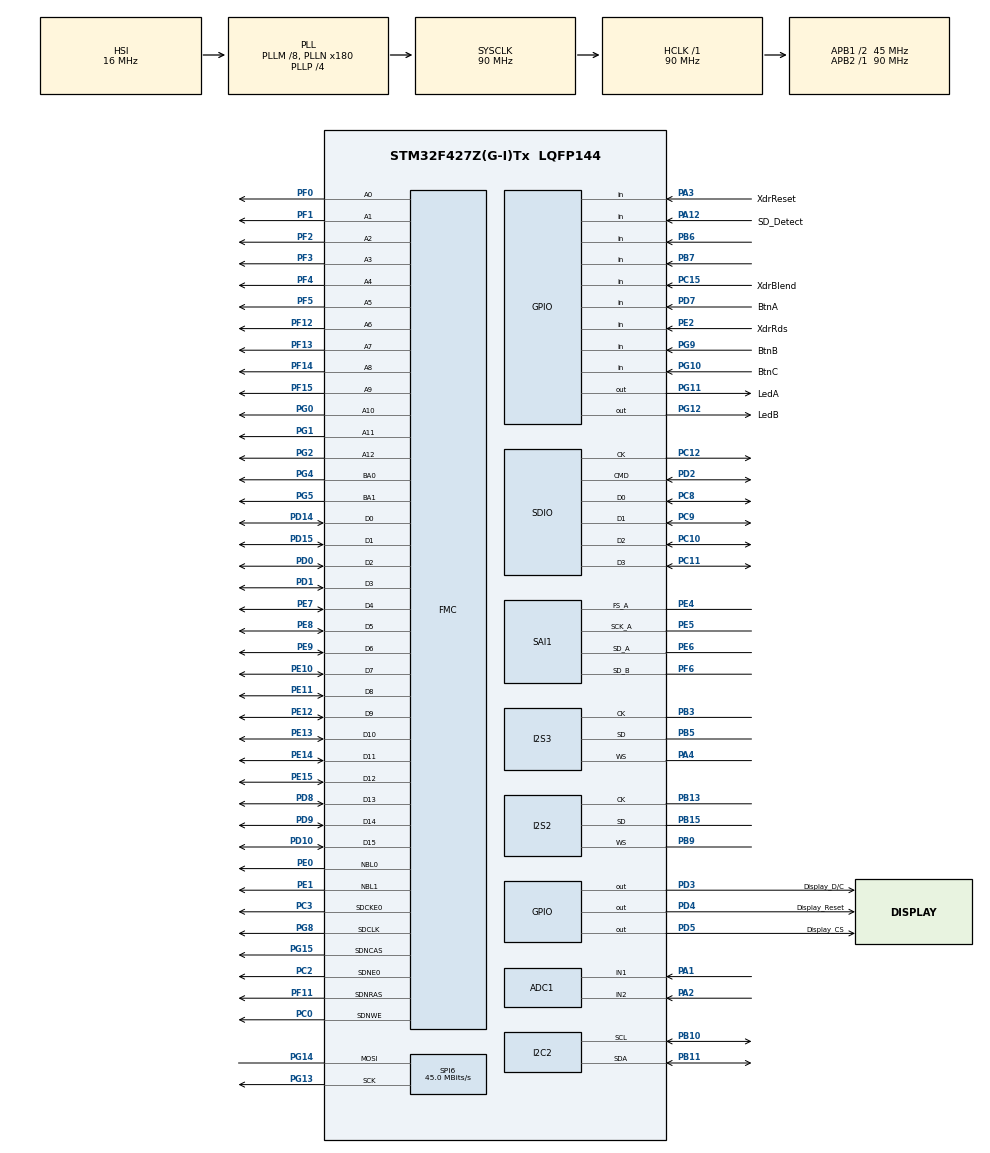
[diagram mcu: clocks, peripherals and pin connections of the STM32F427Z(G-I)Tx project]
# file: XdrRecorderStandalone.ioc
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ADC1.Channel-3\#ChannelRegularConversion=ADC_CHANNEL_1
ADC1.NbrOfConversionFlag=1
ADC1.Rank-3\#ChannelRegularConversion=1
ADC1.SamplingTime-3\#ChannelRegularConversion=ADC_SAMPLETIME_3CYCLES
ADC1.master=1
DMA2D.ColorMode=DMA2D_OUTPUT_RGB565
DMA2D.OutputOffset=1
Dma.Request0=SAI1_A
Dma.Request1=SAI1_B
Dma.Request2=SPI2_RX
Dma.Request3=SPI6_TX
Dma.Request4=SDIO_RX
Dma.Request5=SDIO_TX
Dma.SAI1_A.0.Direction=DMA_PERIPH_TO_MEMORY
Dma.SAI1_A.0.FIFOMode=DMA_FIFOMODE_DISABLE
Dma.SAI1_A.0.Instance=DMA2_Stream1
Dma.SAI1_A.0.MemDataAlignment=DMA_MDATAALIGN_WORD
Dma.SAI1_A.0.MemInc=DMA_MINC_ENABLE
Dma.SAI1_A.0.Mode=DMA_CIRCULAR
Dma.SAI1_A.0.PeriphDataAlignment=DMA_PDATAALIGN_WORD
Dma.SAI1_A.0.PeriphInc=DMA_PINC_DISABLE
Dma.SAI1_A.0.Priority=DMA_PRIORITY_HIGH
Dma.SAI1_B.1.Direction=DMA_PERIPH_TO_MEMORY
Dma.SAI1_B.1.FIFOMode=DMA_FIFOMODE_DISABLE
Dma.SAI1_B.1.Instance=DMA2_Stream4
Dma.SAI1_B.1.MemDataAlignment=DMA_MDATAALIGN_HALFWORD
Dma.SAI1_B.1.MemInc=DMA_MINC_ENABLE
Dma.SAI1_B.1.Mode=DMA_CIRCULAR
Dma.SAI1_B.1.PeriphDataAlignment=DMA_PDATAALIGN_HALFWORD
Dma.SAI1_B.1.PeriphInc=DMA_PINC_DISABLE
Dma.SAI1_B.1.Priority=DMA_PRIORITY_HIGH
Dma.SDIO_RX.4.Direction=DMA_PERIPH_TO_MEMORY
Dma.SDIO_RX.4.FIFOMode=DMA_FIFOMODE_ENABLE
Dma.SDIO_RX.4.FIFOThreshold=DMA_FIFO_THRESHOLD_FULL
Dma.SDIO_RX.4.Instance=DMA2_Stream3
Dma.SDIO_RX.4.MemBurst=DMA_MBURST_INC4
Dma.SDIO_RX.4.MemDataAlignment=DMA_MDATAALIGN_WORD
Dma.SDIO_RX.4.MemInc=DMA_MINC_ENABLE
Dma.SDIO_RX.4.Mode=DMA_PFCTRL
Dma.SDIO_RX.4.PeriphBurst=DMA_PBURST_INC4
Dma.SDIO_RX.4.PeriphDataAlignment=DMA_PDATAALIGN_WORD
Dma.SDIO_RX.4.PeriphInc=DMA_PINC_DISABLE
Dma.SDIO_RX.4.Priority=DMA_PRIORITY_VERY_HIGH
Dma.SDIO_TX.5.Direction=DMA_MEMORY_TO_PERIPH
Dma.SDIO_TX.5.FIFOMode=DMA_FIFOMODE_ENABLE
Dma.SDIO_TX.5.FIFOThreshold=DMA_FIFO_THRESHOLD_FULL
Dma.SDIO_TX.5.Instance=DMA2_Stream6
Dma.SDIO_TX.5.MemBurst=DMA_MBURST_INC4
Dma.SDIO_TX.5.MemDataAlignment=DMA_MDATAALIGN_WORD
Dma.SDIO_TX.5.MemInc=DMA_MINC_ENABLE
Dma.SDIO_TX.5.Mode=DMA_PFCTRL
Dma.SDIO_TX.5.PeriphBurst=DMA_PBURST_INC4
Dma.SDIO_TX.5.PeriphDataAlignment=DMA_PDATAALIGN_WORD
Dma.SDIO_TX.5.PeriphInc=DMA_PINC_DISABLE
Dma.SDIO_TX.5.Priority=DMA_PRIORITY_VERY_HIGH
Dma.SPI2_RX.2.Direction=DMA_PERIPH_TO_MEMORY
Dma.SPI2_RX.2.FIFOMode=DMA_FIFOMODE_DISABLE
Dma.SPI2_RX.2.Instance=DMA1_Stream3
Dma.SPI2_RX.2.MemDataAlignment=DMA_MDATAALIGN_WORD
Dma.SPI2_RX.2.MemInc=DMA_MINC_ENABLE
Dma.SPI2_RX.2.Mode=DMA_CIRCULAR
Dma.SPI2_RX.2.PeriphDataAlignment=DMA_PDATAALIGN_WORD
Dma.SPI2_RX.2.PeriphInc=DMA_PINC_DISABLE
Dma.SPI2_RX.2.Priority=DMA_PRIORITY_HIGH
Dma.SPI6_TX.3.Direction=DMA_MEMORY_TO_PERIPH
Dma.SPI6_TX.3.FIFOMode=DMA_FIFOMODE_DISABLE
Dma.SPI6_TX.3.Instance=DMA2_Stream5
Dma.SPI6_TX.3.MemDataAlignment=DMA_MDATAALIGN_BYTE
Dma.SPI6_TX.3.MemInc=DMA_MINC_ENABLE
Dma.SPI6_TX.3.Mode=DMA_NORMAL
Dma.SPI6_TX.3.PeriphDataAlignment=DMA_PDATAALIGN_BYTE
Dma.SPI6_TX.3.PeriphInc=DMA_PINC_DISABLE
Dma.SPI6_TX.3.Priority=DMA_PRIORITY_LOW
FATFS.BSP.number=1
FATFS.USE_DMA_CODE_SD=1
FATFS._FS_EXFAT=1
FATFS._USE_LFN=3
FATFS0.BSP.STBoard=false
FATFS0.BSP.api=Unknown
FATFS0.BSP.instance=PA12
FATFS0.BSP.ip=GPIO
FATFS0.BSP.mode=Input
FATFS0.BSP.name=Detect_SDIO
FATFS0.BSP.solution=PA12
FMC.CASLatency1=FMC_SDRAM_CAS_LATENCY_3
FMC.ColumnBitsNumber1=FMC_SDRAM_COLUMN_BITS_NUM_9
FMC.ExitSelfRefreshDelay1=8
FMC.LoadToActiveDelay1=2
FMC.RCDDelay1=2
FMC.RPDelay1=2
FMC.ReadBurst1=FMC_SDRAM_RBURST_ENABLE
FMC.ReadPipeDelay1=FMC_SDRAM_RPIPE_DELAY_1
FMC.RowCycleDelay1=7
FMC.SDClockPeriod1=FMC_SDRAM_CLOCK_PERIOD_2
FMC.SelfRefreshTime1=6
FMC.WriteRecoveryTime1=5
I2C2.I2C_Mode=I2C_Fast
I2S2.AudioFreq=I2S_AUDIOFREQ_44K
I2S2.DataFormat=I2S_DATAFORMAT_32B
I2S2.ErrorAudioFreq=0.26 %
I2S2.FullDuplexMode=I2S_FULLDUPLEXMODE_DISABLE
I2S2.Instance=SPI$Index
I2S2.Mode=I2S_MODE_SLAVE_RX
I2S2.RealAudioFreq=44.117 KHz
I2S2.VirtualMode=I2S_MODE_SLAVE
I2S3.AudioFreq=I2S_AUDIOFREQ_44K
I2S3.ErrorAudioFreq=0.26 %
I2S3.FullDuplexMode=I2S_FULLDUPLEXMODE_DISABLE
I2S3.Instance=SPI$Index
I2S3.RealAudioFreq=44.117 KHz
I2S3.VirtualMode=I2S_MODE_SLAVE
Mcu.Family=STM32F4
Mcu.Name=STM32F427Z(G-I)Tx
Mcu.Package=LQFP144
NVIC.DMA1_Stream3_IRQn=true\:0\:0\:false\:false\:true\:false\:true\:true
NVIC.DMA2D_IRQn=true\:0\:0\:false\:false\:true\:true\:true\:true
NVIC.DMA2_Stream1_IRQn=true\:14\:0\:true\:false\:true\:false\:true\:true
NVIC.DMA2_Stream3_IRQn=true\:0\:0\:false\:false\:true\:false\:true\:true
NVIC.DMA2_Stream4_IRQn=true\:14\:0\:true\:false\:true\:false\:true\:true
NVIC.DMA2_Stream5_IRQn=true\:0\:0\:false\:false\:true\:false\:true\:true
NVIC.DMA2_Stream6_IRQn=true\:0\:0\:false\:false\:true\:false\:true\:true
NVIC.FMC_IRQn=true\:0\:0\:false\:false\:true\:true\:true\:true
NVIC.PriorityGroup=NVIC_PRIORITYGROUP_4
NVIC.SAI1_IRQn=true\:0\:0\:false\:false\:true\:true\:true\:true
NVIC.SDIO_IRQn=true\:0\:0\:true\:false\:true\:true\:true\:true
NVIC.SPI2_IRQn=true\:0\:0\:false\:false\:true\:true\:true\:true
NVIC.SPI6_IRQn=true\:0\:0\:false\:false\:true\:true\:true\:true
PA1.Signal=ADCx_IN1
PA12.GPIO_Label=SD_Detect
PA12.Signal=GPIO_Input
PA13.Mode=Serial_Wire
PA13.Signal=SYS_JTMS-SWDIO
PA14.Mode=Serial_Wire
PA14.Signal=SYS_JTCK-SWCLK
PA2.Signal=ADCx_IN2
PA3.GPIO_Label=XdrReset
PA3.Signal=GPIO_Input
PA4.Mode=Half_Duplex_Slave
PA4.Signal=I2S3_WS
PB10.Mode=I2C
PB10.Signal=I2C2_SCL
PB11.Mode=I2C
PB11.Signal=I2C2_SDA
PB13.Mode=Half_Duplex_Slave
PB13.Signal=I2S2_CK
PB15.Mode=Half_Duplex_Slave
PB15.Signal=I2S2_SD
PB3.Mode=Half_Duplex_Slave
PB3.Signal=I2S3_CK
PB5.Mode=Half_Duplex_Slave
PB5.Signal=I2S3_SD
PB6.Signal=GPIO_Input
PB7.Signal=GPIO_Input
PB9.Mode=Half_Duplex_Slave
PB9.Signal=I2S2_WS
PC0.Signal=FMC_SDNWE
PC10.Mode=SD_4_bits_Wide_bus
PC10.Signal=SDIO_D2
PC11.Mode=SD_4_bits_Wide_bus
PC11.Signal=SDIO_D3
PC12.Mode=SD_4_bits_Wide_bus
PC12.Signal=SDIO_CK
PC15/OSC32_OUT.GPIO_Label=XdrBlend
PC15/OSC32_OUT.Signal=GPIO_Input
PC2.Mode=SdramChipSelect1_1
PC2.Signal=FMC_SDNE0
PC3.Mode=SdramChipSelect1_1
PC3.Signal=FMC_SDCKE0
PC8.Mode=SD_4_bits_Wide_bus
PC8.Signal=SDIO_D0
PC9.Mode=SD_4_bits_Wide_bus
PC9.Signal=SDIO_D1
PD0.Signal=FMC_D2_DA2
PD1.Signal=FMC_D3_DA3
PD10.Signal=FMC_D15_DA15
PD14.Signal=FMC_D0_DA0
PD15.Signal=FMC_D1_DA1
PD2.Mode=SD_4_bits_Wide_bus
PD2.Signal=SDIO_CMD
PD3.GPIO_Label=Display_D/C
PD3.Signal=GPIO_Output
PD4.GPIO_Label=Display_Reset
PD4.Signal=GPIO_Output
PD5.GPIO_Label=Display_CS
PD5.Signal=GPIO_Output
PD7.GPIO_Label=BtnA
PD7.Signal=GPIO_Input
PD8.Signal=FMC_D13_DA13
PD9.Signal=FMC_D14_DA14
PE0.Signal=FMC_NBL0
PE1.Signal=FMC_NBL1
PE10.Signal=FMC_D7_DA7
PE11.Signal=FMC_D8_DA8
PE12.Signal=FMC_D9_DA9
PE13.Signal=FMC_D10_DA10
PE14.Signal=FMC_D11_DA11
PE15.Signal=FMC_D12_DA12
PE2.GPIO_Label=XdrRds
PE2.Signal=GPIO_Input
PE4.GPIO_PuPd=GPIO_PULLDOWN
PE4.Mode=SAI_A_AsyncSlave
PE4.Signal=SAI1_FS_A
PE5.GPIO_PuPd=GPIO_PULLDOWN
PE5.Mode=SAI_A_AsyncSlave
PE5.Signal=SAI1_SCK_A
PE6.GPIO_PuPd=GPIO_PULLDOWN
PE6.Mode=SAI_A_AsyncSlave
PE6.Signal=SAI1_SD_A
PE7.Signal=FMC_D4_DA4
PE8.Signal=FMC_D5_DA5
PE9.Signal=FMC_D6_DA6
PF0.Signal=FMC_A0
PF1.Signal=FMC_A1
PF11.Signal=FMC_SDNRAS
PF12.Signal=FMC_A6
PF13.Signal=FMC_A7
PF14.Signal=FMC_A8
PF15.Signal=FMC_A9
PF2.Signal=FMC_A2
PF3.Signal=FMC_A3
PF4.Signal=FMC_A4
PF5.Signal=FMC_A5
PF6.GPIO_PuPd=GPIO_PULLDOWN
PF6.Mode=SAI_B_SyncSlave
PF6.Signal=SAI1_SD_B
PG0.Signal=FMC_A10
PG1.Signal=FMC_A11
PG10.GPIO_Label=BtnC
PG10.Signal=GPIO_Input
PG11.GPIO_Label=LedA
PG11.Signal=GPIO_Output
PG12.GPIO_Label=LedB
PG12.Signal=GPIO_Output
PG13.Mode=Simplex_Bidirectional_Master
PG13.Signal=SPI6_SCK
PG14.Mode=Simplex_Bidirectional_Master
PG14.Signal=SPI6_MOSI
PG15.Signal=FMC_SDNCAS
PG2.Signal=FMC_A12
PG4.Signal=FMC_A14_BA0
PG5.Signal=FMC_A15_BA1
PG8.Signal=FMC_SDCLK
PG9.GPIO_Label=BtnB
PG9.Signal=GPIO_Input
ProjectManager.HeapSize=0x200
ProjectManager.StackSize=0x400
ProjectManager.TargetToolchain=STM32CubeIDE
RCC.48MHZClocksFreq_Value=36000000
RCC.AHBFreq_Value=90000000
RCC.APB1CLKDivider=RCC_HCLK_DIV2
RCC.APB1Freq_Value=45000000
RCC.APB1TimFreq_Value=90000000
RCC.APB2Freq_Value=90000000
RCC.APB2TimFreq_Value=90000000
RCC.CortexFreq_Value=90000000
RCC.DATA_CACHE_ENABLE=0
RCC.HCLKFreq_Value=90000000
RCC.HSE_VALUE=25000000
RCC.HSI_VALUE=16000000
RCC.LSE_VALUE=32768
RCC.PLLI2SQ=8
RCC.PLLM=8
RCC.PLLN=180
RCC.PLLP=RCC_PLLP_DIV4
RCC.PLLQ=10
RCC.PLLSAIN=120
RCC.PLLSAIQ=2
RCC.PREFETCH_ENABLE=0
RCC.SYSCLKFreq_VALUE=90000000
RCC.SYSCLKSource=RCC_SYSCLKSOURCE_PLLCLK
RCC.VCOOutputFreq_Value=360000000
SAI1.ActiveFrameLength-SAI_A_AsyncSlave=16
SAI1.ActiveFrameLength-SAI_B_SyncSlave=16
SAI1.ClockStrobing-SAI_A_AsyncSlave=SAI_CLOCKSTROBING_RISINGEDGE
SAI1.ClockStrobing-SAI_B_SyncSlave=SAI_CLOCKSTROBING_RISINGEDGE
SAI1.DataSize-SAI_A_AsyncSlave=SAI_DATASIZE_16
SAI1.DataSize-SAI_B_SyncSlave=SAI_DATASIZE_16
SAI1.FIFOThreshold-SAI_A_AsyncSlave=SAI_FIFOTHRESHOLD_EMPTY
SAI1.FIFOThreshold-SAI_B_SyncSlave=SAI_FIFOTHRESHOLD_EMPTY
SAI1.FSDefinition-SAI_A_AsyncSlave=SAI_FS_STARTFRAME
SAI1.FSDefinition-SAI_B_SyncSlave=SAI_FS_STARTFRAME
SAI1.FSOffset-SAI_A_AsyncSlave=SAI_FS_BEFOREFIRSTBIT
SAI1.FSOffset-SAI_B_SyncSlave=SAI_FS_BEFOREFIRSTBIT
SAI1.FSPolarity-SAI_A_AsyncSlave=SAI_FS_ACTIVE_LOW
SAI1.FSPolarity-SAI_B_SyncSlave=SAI_FS_ACTIVE_LOW
SAI1.FirstBitOffset-SAI_A_AsyncSlave=0
SAI1.FrameLength-SAI_A_AsyncSlave=32
SAI1.FrameLength-SAI_B_SyncSlave=32
SAI1.Instance-SAI_A_AsyncSlave=SAI$Index_Block_A
SAI1.Instance-SAI_B_SyncSlave=SAI$Index_Block_B
SAI1.SlotActive-SAI_A_AsyncSlave=0x0000FFFF
SAI1.SlotActive-SAI_B_SyncSlave=0x0000FFFF
SAI1.SlotNumber-SAI_A_AsyncSlave=2
SAI1.SlotNumber-SAI_B_SyncSlave=2
SAI1.SlotSize-SAI_A_AsyncSlave=SAI_SLOTSIZE_16B
SAI1.SlotSize-SAI_B_SyncSlave=SAI_SLOTSIZE_16B
SAI1.Synchro_A=SAI_ASYNCHRONOUS
SAI1.Synchro_B=SAI_SYNCHRONOUS
SAI1.VirtualMode-SAI_A_AsyncSlave=VM_SLAVE
SAI1.VirtualMode-SAI_B_SyncSlave=VM_SLAVE
SAI1.VirtualSlotActive-SAI_A_AsyncSlave=SAI_SLOTACTIVE_ALL
SAI1.VirtualSlotActive-SAI_B_SyncSlave=SAI_SLOTACTIVE_ALL
SDIO.ClockDiv=0
SH.ADCx_IN1.0=ADC1_IN1,IN1
SH.ADCx_IN2.0=ADC1_IN2,IN2
SH.FMC_A0.0=FMC_A0,13b-sda1
SH.FMC_A1.0=FMC_A1,13b-sda1
SH.FMC_A10.0=FMC_A10,13b-sda1
SH.FMC_A11.0=FMC_A11,13b-sda1
SH.FMC_A12.0=FMC_A12,13b-sda1
SH.FMC_A14_BA0.0=FMC_BA0,FourSdramBanks1
SH.FMC_A15_BA1.0=FMC_BA1,FourSdramBanks1
SH.FMC_A2.0=FMC_A2,13b-sda1
SH.FMC_A3.0=FMC_A3,13b-sda1
SH.FMC_A4.0=FMC_A4,13b-sda1
SH.FMC_A5.0=FMC_A5,13b-sda1
SH.FMC_A6.0=FMC_A6,13b-sda1
SH.FMC_A7.0=FMC_A7,13b-sda1
SH.FMC_A8.0=FMC_A8,13b-sda1
SH.FMC_A9.0=FMC_A9,13b-sda1
SH.FMC_D0_DA0.0=FMC_D0,sd-16b-d1
SH.FMC_D10_DA10.0=FMC_D10,sd-16b-d1
SH.FMC_D11_DA11.0=FMC_D11,sd-16b-d1
SH.FMC_D12_DA12.0=FMC_D12,sd-16b-d1
SH.FMC_D13_DA13.0=FMC_D13,sd-16b-d1
SH.FMC_D14_DA14.0=FMC_D14,sd-16b-d1
SH.FMC_D15_DA15.0=FMC_D15,sd-16b-d1
SH.FMC_D1_DA1.0=FMC_D1,sd-16b-d1
SH.FMC_D2_DA2.0=FMC_D2,sd-16b-d1
SH.FMC_D3_DA3.0=FMC_D3,sd-16b-d1
SH.FMC_D4_DA4.0=FMC_D4,sd-16b-d1
SH.FMC_D5_DA5.0=FMC_D5,sd-16b-d1
SH.FMC_D6_DA6.0=FMC_D6,sd-16b-d1
SH.FMC_D7_DA7.0=FMC_D7,sd-16b-d1
SH.FMC_D8_DA8.0=FMC_D8,sd-16b-d1
SH.FMC_D9_DA9.0=FMC_D9,sd-16b-d1
SH.FMC_NBL0.0=FMC_NBL0,Sd2ByteEnable1
SH.FMC_NBL1.0=FMC_NBL1,Sd2ByteEnable1
SH.FMC_SDCLK.0=FMC_SDCLK,13b-sda1
SH.FMC_SDNCAS.0=FMC_SDNCAS,13b-sda1
SH.FMC_SDNRAS.0=FMC_SDNRAS,13b-sda1
SH.FMC_SDNWE.0=FMC_SDNWE,13b-sda1
SPI6.BaudRatePrescaler=SPI_BAUDRATEPRESCALER_2
SPI6.CalculateBaudRate=45.0 MBits/s
SPI6.Direction=SPI_DIRECTION_1LINE
SPI6.Mode=SPI_MODE_MASTER
SPI6.VirtualType=VM_MASTER
VP_DMA2D_VS_DMA2D.Mode=DMA2D_Activate
VP_FATFS_VS_SDIO.Mode=SDIO
board=custom

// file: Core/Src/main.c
/* USER CODE BEGIN Header */
/**
  ******************************************************************************
  * @file           : main.c
  * @brief          : Main program body
  ******************************************************************************
  * @attention
  *
  * Copyright (c) 2022 STMicroelectronics.
  * All rights reserved.
  *
  * This software is licensed under terms that can be found in the LICENSE file
  * in the root directory of this software component.
  * If no LICENSE file comes with this software, it is provided AS-IS.
  *
  ******************************************************************************
  */
/* USER CODE END Header */
#include <gui/views/captureview.h>
#include "main.h"
#include "fatfs.h"

/* USER CODE BEGIN Includes */
#include "sdram.h"
#include "recorder/recorder.h"
#include "recorder/wav.h"
#include "sdman.h"
#include "gui/assets.h"
#include "gui/display.h"
#include "gui/viewman.h"
#include "gui/views/splash.h"
/* USER CODE END Includes */

ADC_HandleTypeDef hadc1;

DMA2D_HandleTypeDef hdma2d;

I2C_HandleTypeDef hi2c2;

I2S_HandleTypeDef hi2s2;
I2S_HandleTypeDef hi2s3;
DMA_HandleTypeDef hdma_spi2_rx;

SAI_HandleTypeDef hsai_BlockA1;
SAI_HandleTypeDef hsai_BlockB1;
DMA_HandleTypeDef hdma_sai1_a;
DMA_HandleTypeDef hdma_sai1_b;

SD_HandleTypeDef hsd;
DMA_HandleTypeDef hdma_sdio_rx;
DMA_HandleTypeDef hdma_sdio_tx;

SPI_HandleTypeDef hspi6;
DMA_HandleTypeDef hdma_spi6_tx;

SDRAM_HandleTypeDef hsdram1;

void SystemClock_Config(void);
void PeriphCommonClock_Config(void);
static void MX_GPIO_Init(void);
static void MX_DMA_Init(void);
static void MX_DMA2D_Init(void);
static void MX_FMC_Init(void);
static void MX_I2S2_Init(void);
static void MX_I2S3_Init(void);
static void MX_SAI1_Init(void);
static void MX_SDIO_SD_Init(void);
static void MX_SPI6_Init(void);
static void MX_I2C2_Init(void);
static void MX_ADC1_Init(void);

/* USER CODE BEGIN 0 */

// USER IMPLIMENTED - Called when a recorder starts. Output should be opened. Returns 1 on success, otherwise 0
int recorder_handler_begin(int index, FIL* output) {
	//Open file
	if (f_open(output, "0:/test.wav", FA_CREATE_ALWAYS | FA_WRITE) != FR_OK)
		return 0;

	//Query
	recorder_class_t info;
	uint8_t state;
	uint64_t receivedSamples;
	uint64_t droppedBuffers;
	recorder_query_instance_info(index, &info, &state, &receivedSamples, &droppedBuffers);

	//Prepare WAV header
	wav_file_header_t wav;
	wav_init_header(&wav, info.output_channels, info.output_bits_per_sample, info.output_sample_rate);
	UINT written;
	f_write(output, &wav, sizeof(wav), &written);
	return 1;
}

// USER IMPLIMENTED - Called when a recorder stops (either normally or with an error). File should be closed by this function.
void recorder_handler_stop(int index, FIL* output, int code) {
	//Query
	recorder_class_t info;
	uint8_t state;
	uint64_t receivedSamples;
	uint64_t droppedBuffers;
	recorder_query_instance_info(index, &info, &state, &receivedSamples, &droppedBuffers);

	//Prepare WAV header
	wav_file_header_t wav;
	wav_init_header(&wav, info.output_channels, info.output_bits_per_sample, info.output_sample_rate);
	wav_calculate_length(&wav, receivedSamples);

	//Rewind to beginning and update WAV header
	UINT written;
	f_lseek(output, 0);
	f_write(output, &wav, sizeof(wav), &written);

	//Finally, close file
	f_close(output);
}

/* USER CODE END 0 */

int main(void)
{

  /* MCU Configuration--------------------------------------------------------*/

  /* Reset of all peripherals, Initializes the Flash interface and the Systick. */
  HAL_Init();

  /* Configure the system clock */
  SystemClock_Config();

/* Configure the peripherals common clocks */
  PeriphCommonClock_Config();

  /* Initialize all configured peripherals */
  MX_GPIO_Init();
  MX_DMA_Init();
  MX_DMA2D_Init();
  MX_FMC_Init();
  MX_I2S2_Init();
  MX_I2S3_Init();
  MX_SAI1_Init();
  MX_SDIO_SD_Init();
  MX_SPI6_Init();
  MX_I2C2_Init();
  MX_ADC1_Init();
  MX_FATFS_Init();
  /* USER CODE BEGIN 2 */

  /*uint32_t test[64];
  HAL_StatusTypeDef result;
  int count = 0;
  do {
	  result = HAL_SAI_Receive(&hsai_BlockA1, test, 64, 9999);
	  count++;
  } while (result == HAL_OK);*/

  //int code = f_mount(&sdman_fs, SDPath, 1);

  //Start the display
  HAL_Delay(250);
  display_fb_clear();
  display_init();
  create_view_splash();
  viewman_tick();

  //Show capture view
  create_view_capture();
  viewman_push_alert(&icon_alert_warn, "SD IO Err!");
  int test = 0;

  /* USER CODE END 2 */

  /* Infinite loop */
  /* USER CODE BEGIN WHILE */
  while (1)
  {
	  //Tick SD card manager
	  sdman_tick();

	  //TEST
	  if (!test && sdman_state == SDMAN_STATE_READY) {
		  recorder_request_start(0);
		  test = 1;
	  }

	  //Tick view
	  viewman_tick();
    /* USER CODE END WHILE */

  }
}

void SystemClock_Config(void)
{
  RCC_OscInitTypeDef RCC_OscInitStruct = {0};
  RCC_ClkInitTypeDef RCC_ClkInitStruct = {0};

  /** Macro to configure SAI1BlockB clock source selection
  */
  __HAL_RCC_SAI_BLOCKBCLKSOURCE_CONFIG(SAI_CLKSOURCE_PLLSAI);

  /** Macro to configure SAI1BlockA clock source selection
  */
  __HAL_RCC_SAI_BLOCKACLKSOURCE_CONFIG(SAI_CLKSOURCE_PLLSAI);

  /** Configure the main internal regulator output voltage
  */
  __HAL_RCC_PWR_CLK_ENABLE();
  __HAL_PWR_VOLTAGESCALING_CONFIG(PWR_REGULATOR_VOLTAGE_SCALE3);

  /** Initializes the RCC Oscillators according to the specified parameters
  * in the RCC_OscInitTypeDef structure.
  */
  RCC_OscInitStruct.OscillatorType = RCC_OSCILLATORTYPE_HSI;
  RCC_OscInitStruct.HSIState = RCC_HSI_ON;
  RCC_OscInitStruct.HSICalibrationValue = RCC_HSICALIBRATION_DEFAULT;
  RCC_OscInitStruct.PLL.PLLState = RCC_PLL_ON;
  RCC_OscInitStruct.PLL.PLLSource = RCC_PLLSOURCE_HSI;
  RCC_OscInitStruct.PLL.PLLM = 8;
  RCC_OscInitStruct.PLL.PLLN = 180;
  RCC_OscInitStruct.PLL.PLLP = RCC_PLLP_DIV4;
  RCC_OscInitStruct.PLL.PLLQ = 10;
  if (HAL_RCC_OscConfig(&RCC_OscInitStruct) != HAL_OK)
  {
    Error_Handler();
  }

  /** Activate the Over-Drive mode
  */
  if (HAL_PWREx_EnableOverDrive() != HAL_OK)
  {
    Error_Handler();
  }

  /** Initializes the CPU, AHB and APB buses clocks
  */
  RCC_ClkInitStruct.ClockType = RCC_CLOCKTYPE_HCLK|RCC_CLOCKTYPE_SYSCLK
                              |RCC_CLOCKTYPE_PCLK1|RCC_CLOCKTYPE_PCLK2;
  RCC_ClkInitStruct.SYSCLKSource = RCC_SYSCLKSOURCE_PLLCLK;
  RCC_ClkInitStruct.AHBCLKDivider = RCC_SYSCLK_DIV1;
  RCC_ClkInitStruct.APB1CLKDivider = RCC_HCLK_DIV2;
  RCC_ClkInitStruct.APB2CLKDivider = RCC_HCLK_DIV1;

  if (HAL_RCC_ClockConfig(&RCC_ClkInitStruct, FLASH_LATENCY_2) != HAL_OK)
  {
    Error_Handler();
  }
}

void PeriphCommonClock_Config(void)
{
  RCC_PeriphCLKInitTypeDef PeriphClkInitStruct = {0};

  /** Initializes the peripherals clock
  */
  PeriphClkInitStruct.PeriphClockSelection = RCC_PERIPHCLK_I2S|RCC_PERIPHCLK_SAI_PLLSAI;
  PeriphClkInitStruct.PLLI2S.PLLI2SN = 192;
  PeriphClkInitStruct.PLLI2S.PLLI2SR = 2;
  PeriphClkInitStruct.PLLSAI.PLLSAIN = 120;
  PeriphClkInitStruct.PLLSAI.PLLSAIQ = 2;
  PeriphClkInitStruct.PLLSAIDivQ = 1;
  if (HAL_RCCEx_PeriphCLKConfig(&PeriphClkInitStruct) != HAL_OK)
  {
    Error_Handler();
  }
}

static void MX_ADC1_Init(void)
{

  ADC_ChannelConfTypeDef sConfig = {0};

  /** Configure the global features of the ADC (Clock, Resolution, Data Alignment and number of conversion)
  */
  hadc1.Instance = ADC1;
  hadc1.Init.ClockPrescaler = ADC_CLOCK_SYNC_PCLK_DIV4;
  hadc1.Init.Resolution = ADC_RESOLUTION_12B;
  hadc1.Init.ScanConvMode = DISABLE;
  hadc1.Init.ContinuousConvMode = DISABLE;
  hadc1.Init.DiscontinuousConvMode = DISABLE;
  hadc1.Init.ExternalTrigConvEdge = ADC_EXTERNALTRIGCONVEDGE_NONE;
  hadc1.Init.ExternalTrigConv = ADC_SOFTWARE_START;
  hadc1.Init.DataAlign = ADC_DATAALIGN_RIGHT;
  hadc1.Init.NbrOfConversion = 1;
  hadc1.Init.DMAContinuousRequests = DISABLE;
  hadc1.Init.EOCSelection = ADC_EOC_SINGLE_CONV;
  if (HAL_ADC_Init(&hadc1) != HAL_OK)
  {
    Error_Handler();
  }

  /** Configure for the selected ADC regular channel its corresponding rank in the sequencer and its sample time.
  */
  sConfig.Channel = ADC_CHANNEL_1;
  sConfig.Rank = 1;
  sConfig.SamplingTime = ADC_SAMPLETIME_3CYCLES;
  if (HAL_ADC_ConfigChannel(&hadc1, &sConfig) != HAL_OK)
  {
    Error_Handler();
  }

}

static void MX_DMA2D_Init(void)
{

  hdma2d.Instance = DMA2D;
  hdma2d.Init.Mode = DMA2D_M2M;
  hdma2d.Init.ColorMode = DMA2D_OUTPUT_RGB565;
  hdma2d.Init.OutputOffset = 1;
  hdma2d.LayerCfg[1].InputOffset = 0;
  hdma2d.LayerCfg[1].InputColorMode = DMA2D_INPUT_RGB565;
  hdma2d.LayerCfg[1].AlphaMode = DMA2D_NO_MODIF_ALPHA;
  hdma2d.LayerCfg[1].InputAlpha = 0;
  if (HAL_DMA2D_Init(&hdma2d) != HAL_OK)
  {
    Error_Handler();
  }
  if (HAL_DMA2D_ConfigLayer(&hdma2d, 1) != HAL_OK)
  {
    Error_Handler();
  }

}

static void MX_I2C2_Init(void)
{

  hi2c2.Instance = I2C2;
  hi2c2.Init.ClockSpeed = 400000;
  hi2c2.Init.DutyCycle = I2C_DUTYCYCLE_2;
  hi2c2.Init.OwnAddress1 = 0;
  hi2c2.Init.AddressingMode = I2C_ADDRESSINGMODE_7BIT;
  hi2c2.Init.DualAddressMode = I2C_DUALADDRESS_DISABLE;
  hi2c2.Init.OwnAddress2 = 0;
  hi2c2.Init.GeneralCallMode = I2C_GENERALCALL_DISABLE;
  hi2c2.Init.NoStretchMode = I2C_NOSTRETCH_DISABLE;
  if (HAL_I2C_Init(&hi2c2) != HAL_OK)
  {
    Error_Handler();
  }

  /** Configure Analogue filter
  */
  if (HAL_I2CEx_ConfigAnalogFilter(&hi2c2, I2C_ANALOGFILTER_ENABLE) != HAL_OK)
  {
    Error_Handler();
  }

  /** Configure Digital filter
  */
  if (HAL_I2CEx_ConfigDigitalFilter(&hi2c2, 0) != HAL_OK)
  {
    Error_Handler();
  }

}

static void MX_I2S2_Init(void)
{

  hi2s2.Instance = SPI2;
  hi2s2.Init.Mode = I2S_MODE_SLAVE_RX;
  hi2s2.Init.Standard = I2S_STANDARD_PHILIPS;
  hi2s2.Init.DataFormat = I2S_DATAFORMAT_32B;
  hi2s2.Init.MCLKOutput = I2S_MCLKOUTPUT_DISABLE;
  hi2s2.Init.AudioFreq = I2S_AUDIOFREQ_44K;
  hi2s2.Init.CPOL = I2S_CPOL_LOW;
  hi2s2.Init.ClockSource = I2S_CLOCK_PLL;
  hi2s2.Init.FullDuplexMode = I2S_FULLDUPLEXMODE_DISABLE;
  if (HAL_I2S_Init(&hi2s2) != HAL_OK)
  {
    Error_Handler();
  }

}

static void MX_I2S3_Init(void)
{

  hi2s3.Instance = SPI3;
  hi2s3.Init.Mode = I2S_MODE_SLAVE_TX;
  hi2s3.Init.Standard = I2S_STANDARD_PHILIPS;
  hi2s3.Init.DataFormat = I2S_DATAFORMAT_16B;
  hi2s3.Init.MCLKOutput = I2S_MCLKOUTPUT_DISABLE;
  hi2s3.Init.AudioFreq = I2S_AUDIOFREQ_44K;
  hi2s3.Init.CPOL = I2S_CPOL_LOW;
  hi2s3.Init.ClockSource = I2S_CLOCK_PLL;
  hi2s3.Init.FullDuplexMode = I2S_FULLDUPLEXMODE_DISABLE;
  if (HAL_I2S_Init(&hi2s3) != HAL_OK)
  {
    Error_Handler();
  }

}

static void MX_SAI1_Init(void)
{

  hsai_BlockA1.Instance = SAI1_Block_A;
  hsai_BlockA1.Init.Protocol = SAI_FREE_PROTOCOL;
  hsai_BlockA1.Init.AudioMode = SAI_MODESLAVE_RX;
  hsai_BlockA1.Init.DataSize = SAI_DATASIZE_16;
  hsai_BlockA1.Init.FirstBit = SAI_FIRSTBIT_MSB;
  hsai_BlockA1.Init.ClockStrobing = SAI_CLOCKSTROBING_RISINGEDGE;
  hsai_BlockA1.Init.Synchro = SAI_ASYNCHRONOUS;
  hsai_BlockA1.Init.OutputDrive = SAI_OUTPUTDRIVE_DISABLE;
  hsai_BlockA1.Init.FIFOThreshold = SAI_FIFOTHRESHOLD_EMPTY;
  hsai_BlockA1.FrameInit.FrameLength = 32;
  hsai_BlockA1.FrameInit.ActiveFrameLength = 16;
  hsai_BlockA1.FrameInit.FSDefinition = SAI_FS_STARTFRAME;
  hsai_BlockA1.FrameInit.FSPolarity = SAI_FS_ACTIVE_LOW;
  hsai_BlockA1.FrameInit.FSOffset = SAI_FS_BEFOREFIRSTBIT;
  hsai_BlockA1.SlotInit.FirstBitOffset = 0;
  hsai_BlockA1.SlotInit.SlotSize = SAI_SLOTSIZE_16B;
  hsai_BlockA1.SlotInit.SlotNumber = 2;
  hsai_BlockA1.SlotInit.SlotActive = 0x0000FFFF;
  if (HAL_SAI_Init(&hsai_BlockA1) != HAL_OK)
  {
    Error_Handler();
  }
  hsai_BlockB1.Instance = SAI1_Block_B;
  hsai_BlockB1.Init.Protocol = SAI_FREE_PROTOCOL;
  hsai_BlockB1.Init.AudioMode = SAI_MODESLAVE_RX;
  hsai_BlockB1.Init.DataSize = SAI_DATASIZE_16;
  hsai_BlockB1.Init.FirstBit = SAI_FIRSTBIT_MSB;
  hsai_BlockB1.Init.ClockStrobing = SAI_CLOCKSTROBING_RISINGEDGE;
  hsai_BlockB1.Init.Synchro = SAI_SYNCHRONOUS;
  hsai_BlockB1.Init.OutputDrive = SAI_OUTPUTDRIVE_DISABLE;
  hsai_BlockB1.Init.FIFOThreshold = SAI_FIFOTHRESHOLD_EMPTY;
  hsai_BlockB1.FrameInit.FrameLength = 32;
  hsai_BlockB1.FrameInit.ActiveFrameLength = 16;
  hsai_BlockB1.FrameInit.FSDefinition = SAI_FS_STARTFRAME;
  hsai_BlockB1.FrameInit.FSPolarity = SAI_FS_ACTIVE_LOW;
  hsai_BlockB1.FrameInit.FSOffset = SAI_FS_BEFOREFIRSTBIT;
  hsai_BlockB1.SlotInit.FirstBitOffset = 0;
  hsai_BlockB1.SlotInit.SlotSize = SAI_SLOTSIZE_16B;
  hsai_BlockB1.SlotInit.SlotNumber = 2;
  hsai_BlockB1.SlotInit.SlotActive = 0x0000FFFF;
  if (HAL_SAI_Init(&hsai_BlockB1) != HAL_OK)
  {
    Error_Handler();
  }

}

static void MX_SDIO_SD_Init(void)
{

  hsd.Instance = SDIO;
  hsd.Init.ClockEdge = SDIO_CLOCK_EDGE_RISING;
  hsd.Init.ClockBypass = SDIO_CLOCK_BYPASS_DISABLE;
  hsd.Init.ClockPowerSave = SDIO_CLOCK_POWER_SAVE_DISABLE;
  hsd.Init.BusWide = SDIO_BUS_WIDE_1B;
  hsd.Init.HardwareFlowControl = SDIO_HARDWARE_FLOW_CONTROL_DISABLE;
  hsd.Init.ClockDiv = 0;

}

static void MX_SPI6_Init(void)
{

  /* SPI6 parameter configuration*/
  hspi6.Instance = SPI6;
  hspi6.Init.Mode = SPI_MODE_MASTER;
  hspi6.Init.Direction = SPI_DIRECTION_1LINE;
  hspi6.Init.DataSize = SPI_DATASIZE_8BIT;
  hspi6.Init.CLKPolarity = SPI_POLARITY_LOW;
  hspi6.Init.CLKPhase = SPI_PHASE_1EDGE;
  hspi6.Init.NSS = SPI_NSS_SOFT;
  hspi6.Init.BaudRatePrescaler = SPI_BAUDRATEPRESCALER_2;
  hspi6.Init.FirstBit = SPI_FIRSTBIT_MSB;
  hspi6.Init.TIMode = SPI_TIMODE_DISABLE;
  hspi6.Init.CRCCalculation = SPI_CRCCALCULATION_DISABLE;
  hspi6.Init.CRCPolynomial = 10;
  if (HAL_SPI_Init(&hspi6) != HAL_OK)
  {
    Error_Handler();
  }

}

static void MX_DMA_Init(void)
{

  /* DMA controller clock enable */
  __HAL_RCC_DMA2_CLK_ENABLE();
  __HAL_RCC_DMA1_CLK_ENABLE();

  /* DMA interrupt init */
  /* DMA1_Stream3_IRQn interrupt configuration */
  HAL_NVIC_SetPriority(DMA1_Stream3_IRQn, 0, 0);
  HAL_NVIC_EnableIRQ(DMA1_Stream3_IRQn);
  /* DMA2_Stream1_IRQn interrupt configuration */
  HAL_NVIC_SetPriority(DMA2_Stream1_IRQn, 14, 0);
  HAL_NVIC_EnableIRQ(DMA2_Stream1_IRQn);
  /* DMA2_Stream3_IRQn interrupt configuration */
  HAL_NVIC_SetPriority(DMA2_Stream3_IRQn, 0, 0);
  HAL_NVIC_EnableIRQ(DMA2_Stream3_IRQn);
  /* DMA2_Stream4_IRQn interrupt configuration */
  HAL_NVIC_SetPriority(DMA2_Stream4_IRQn, 14, 0);
  HAL_NVIC_EnableIRQ(DMA2_Stream4_IRQn);
  /* DMA2_Stream5_IRQn interrupt configuration */
  HAL_NVIC_SetPriority(DMA2_Stream5_IRQn, 0, 0);
  HAL_NVIC_EnableIRQ(DMA2_Stream5_IRQn);
  /* DMA2_Stream6_IRQn interrupt configuration */
  HAL_NVIC_SetPriority(DMA2_Stream6_IRQn, 0, 0);
  HAL_NVIC_EnableIRQ(DMA2_Stream6_IRQn);

}

/* FMC initialization function */
static void MX_FMC_Init(void)
{

  FMC_SDRAM_TimingTypeDef SdramTiming = {0};

  /** Perform the SDRAM1 memory initialization sequence
  */
  hsdram1.Instance = FMC_SDRAM_DEVICE;
  /* hsdram1.Init */
  hsdram1.Init.SDBank = FMC_SDRAM_BANK1;
  hsdram1.Init.ColumnBitsNumber = FMC_SDRAM_COLUMN_BITS_NUM_9;
  hsdram1.Init.RowBitsNumber = FMC_SDRAM_ROW_BITS_NUM_13;
  hsdram1.Init.MemoryDataWidth = FMC_SDRAM_MEM_BUS_WIDTH_16;
  hsdram1.Init.InternalBankNumber = FMC_SDRAM_INTERN_BANKS_NUM_4;
  hsdram1.Init.CASLatency = FMC_SDRAM_CAS_LATENCY_3;
  hsdram1.Init.WriteProtection = FMC_SDRAM_WRITE_PROTECTION_DISABLE;
  hsdram1.Init.SDClockPeriod = FMC_SDRAM_CLOCK_PERIOD_2;
  hsdram1.Init.ReadBurst = FMC_SDRAM_RBURST_ENABLE;
  hsdram1.Init.ReadPipeDelay = FMC_SDRAM_RPIPE_DELAY_1;
  /* SdramTiming */
  SdramTiming.LoadToActiveDelay = 2;
  SdramTiming.ExitSelfRefreshDelay = 8;
  SdramTiming.SelfRefreshTime = 6;
  SdramTiming.RowCycleDelay = 7;
  SdramTiming.WriteRecoveryTime = 5;
  SdramTiming.RPDelay = 2;
  SdramTiming.RCDDelay = 2;

  if (HAL_SDRAM_Init(&hsdram1, &SdramTiming) != HAL_OK)
  {
    Error_Handler( );
  }

  /* USER CODE BEGIN FMC_Init 2 */
  W9825G6KH_init(&hsdram1);
  /* USER CODE END FMC_Init 2 */
}

static void MX_GPIO_Init(void)
{
  GPIO_InitTypeDef GPIO_InitStruct = {0};

  /* GPIO Ports Clock Enable */
  __HAL_RCC_GPIOE_CLK_ENABLE();
  __HAL_RCC_GPIOC_CLK_ENABLE();
  __HAL_RCC_GPIOF_CLK_ENABLE();
  __HAL_RCC_GPIOA_CLK_ENABLE();
  __HAL_RCC_GPIOG_CLK_ENABLE();
  __HAL_RCC_GPIOB_CLK_ENABLE();
  __HAL_RCC_GPIOD_CLK_ENABLE();

  /*Configure GPIO pin Output Level */
  HAL_GPIO_WritePin(GPIOD, Display_D_C_Pin|Display_Reset_Pin|Display_CS_Pin, GPIO_PIN_RESET);

  /*Configure GPIO pin Output Level */
  HAL_GPIO_WritePin(GPIOG, LedA_Pin|LedB_Pin, GPIO_PIN_RESET);

  /*Configure GPIO pin : XdrRds_Pin */
  GPIO_InitStruct.Pin = XdrRds_Pin;
  GPIO_InitStruct.Mode = GPIO_MODE_INPUT;
  GPIO_InitStruct.Pull = GPIO_NOPULL;
  HAL_GPIO_Init(XdrRds_GPIO_Port, &GPIO_InitStruct);

  /*Configure GPIO pin : XdrBlend_Pin */
  GPIO_InitStruct.Pin = XdrBlend_Pin;
  GPIO_InitStruct.Mode = GPIO_MODE_INPUT;
  GPIO_InitStruct.Pull = GPIO_NOPULL;
  HAL_GPIO_Init(XdrBlend_GPIO_Port, &GPIO_InitStruct);

  /*Configure GPIO pins : XdrReset_Pin SD_Detect_Pin */
  GPIO_InitStruct.Pin = XdrReset_Pin|SD_Detect_Pin;
  GPIO_InitStruct.Mode = GPIO_MODE_INPUT;
  GPIO_InitStruct.Pull = GPIO_NOPULL;
  HAL_GPIO_Init(GPIOA, &GPIO_InitStruct);

  /*Configure GPIO pins : Display_D_C_Pin Display_Reset_Pin Display_CS_Pin */
  GPIO_InitStruct.Pin = Display_D_C_Pin|Display_Reset_Pin|Display_CS_Pin;
  GPIO_InitStruct.Mode = GPIO_MODE_OUTPUT_PP;
  GPIO_InitStruct.Pull = GPIO_NOPULL;
  GPIO_InitStruct.Speed = GPIO_SPEED_FREQ_LOW;
  HAL_GPIO_Init(GPIOD, &GPIO_InitStruct);

  /*Configure GPIO pin : BtnA_Pin */
  GPIO_InitStruct.Pin = BtnA_Pin;
  GPIO_InitStruct.Mode = GPIO_MODE_INPUT;
  GPIO_InitStruct.Pull = GPIO_NOPULL;
  HAL_GPIO_Init(BtnA_GPIO_Port, &GPIO_InitStruct);

  /*Configure GPIO pins : BtnB_Pin BtnC_Pin */
  GPIO_InitStruct.Pin = BtnB_Pin|BtnC_Pin;
  GPIO_InitStruct.Mode = GPIO_MODE_INPUT;
  GPIO_InitStruct.Pull = GPIO_NOPULL;
  HAL_GPIO_Init(GPIOG, &GPIO_InitStruct);

  /*Configure GPIO pins : LedA_Pin LedB_Pin */
  GPIO_InitStruct.Pin = LedA_Pin|LedB_Pin;
  GPIO_InitStruct.Mode = GPIO_MODE_OUTPUT_PP;
  GPIO_InitStruct.Pull = GPIO_NOPULL;
  GPIO_InitStruct.Speed = GPIO_SPEED_FREQ_LOW;
  HAL_GPIO_Init(GPIOG, &GPIO_InitStruct);

  /*Configure GPIO pins : PB6 PB7 */
  GPIO_InitStruct.Pin = GPIO_PIN_6|GPIO_PIN_7;
  GPIO_InitStruct.Mode = GPIO_MODE_INPUT;
  GPIO_InitStruct.Pull = GPIO_NOPULL;
  HAL_GPIO_Init(GPIOB, &GPIO_InitStruct);

}

void Error_Handler(void)
{
  __disable_irq();
  while (1)
  {
  }
}
